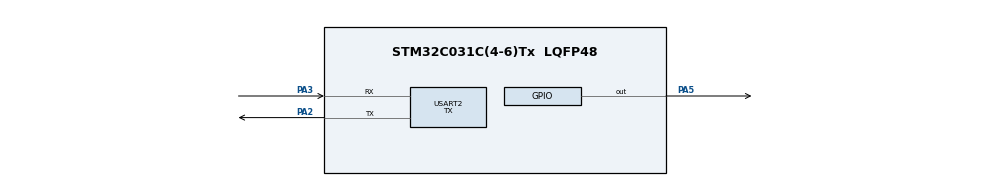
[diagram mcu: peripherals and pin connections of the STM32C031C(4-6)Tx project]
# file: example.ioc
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Mcu.Family=STM32C0
Mcu.Name=STM32C031C(4-6)Tx
Mcu.Package=LQFP48
NVIC.TimeBase=None
PA13.Mode=Serial_Wire
PA13.Signal=DEBUG_SWDIO
PA14-BOOT0.Mode=Serial_Wire
PA14-BOOT0.Signal=DEBUG_SWCLK
PA2.Mode=Asynchronous
PA2.Signal=USART2_TX
PA3.Mode=Asynchronous
PA3.Signal=USART2_RX
PA5.Signal=GPIO_Output
ProjectManager.HeapSize=0x200
ProjectManager.StackSize=0x400
ProjectManager.TargetToolchain=CMake
RCC.ADCFreq_Value=48000000
RCC.AHBFreq_Value=48000000
RCC.CortexFreq_Value=48000000
RCC.EXTERNAL_CLOCK_VALUE=12288000
RCC.HCLKFreq_Value=48000000
RCC.HSE_VALUE=8000000
RCC.HSISYSCLKDivider=RCC_HSI_DIV1
RCC.HSI_VALUE=48000000
RCC.LSE_VALUE=32768
RCC.SYSCLKFreq_VALUE=48000000
USART2.Mode=MODE_TX
USART2.VirtualMode-Asynchronous=VM_ASYNC
VP_SYS_VS_None.Mode=None
board=custom

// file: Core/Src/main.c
/* USER CODE BEGIN Header */
/**
  ******************************************************************************
  * @file           : main.c
  * @brief          : Main program body
  ******************************************************************************
  * @attention
  *
  * Copyright (c) 2026 STMicroelectronics.
  * All rights reserved.
  *
  * This software is licensed under terms that can be found in the LICENSE file
  * in the root directory of this software component.
  * If no LICENSE file comes with this software, it is provided AS-IS.
  *
  ******************************************************************************
  */
/* USER CODE END Header */
#include "main.h"

/* USER CODE BEGIN Includes */
#include "m0ss.h"
/* USER CODE END Includes */

/* USER CODE BEGIN PD */
#define BLINK_THREAD_STACK_BUF_CAPACITY 1024
#define UART_THREAD_STACK_BUF_CAPACITY 1024
/* USER CODE END PD */

UART_HandleTypeDef huart2;

/* USER CODE BEGIN PV */
_Alignas(8) static uint8_t blink_thread_stack_buf[BLINK_THREAD_STACK_BUF_CAPACITY];
_Alignas(8) static uint8_t uart_thread_stack_buf[UART_THREAD_STACK_BUF_CAPACITY];
/* USER CODE END PV */

void SystemClock_Config(void);
static void MX_GPIO_Init(void);
static void MX_USART2_UART_Init(void);
/* USER CODE BEGIN PFP */
void blink_thread_func()
{
    while (1) {
        HAL_GPIO_TogglePin(GPIOA, GPIO_PIN_5);

        m0ss_delay(250);
    }
}

void uart_thread_func()
{
    const char* message = "Hello, m0ss!\n";

    while (1) {
        HAL_UART_Transmit(&huart2, (uint8_t*)message, 13, HAL_MAX_DELAY);

        m0ss_delay(1000);
    }
}
/* USER CODE END PFP */

/* USER CODE BEGIN 0 */
// Note: Let the RTOS configure the SysTick.
HAL_StatusTypeDef HAL_InitTick(uint32_t TickPriority) {
    return HAL_OK;
}
/* USER CODE END 0 */

int main(void)
{

  /* MCU Configuration--------------------------------------------------------*/

  /* Reset of all peripherals, Initializes the Flash interface and the Systick. */
  HAL_Init();

  /* Configure the system clock */
  SystemClock_Config();

  /* Initialize all configured peripherals */
  MX_GPIO_Init();
  MX_USART2_UART_Init();
  /* USER CODE BEGIN 2 */
  m0ss_thread blink_thread;
  m0ss_thread uart_thread;

  m0ss_thread_create(&blink_thread, M0SS_THREAD_PRIORITY_LOWEST, blink_thread_func, blink_thread_stack_buf, BLINK_THREAD_STACK_BUF_CAPACITY);
  m0ss_thread_create(&uart_thread, M0SS_THREAD_PRIORITY_LOWEST + 1, uart_thread_func, uart_thread_stack_buf, UART_THREAD_STACK_BUF_CAPACITY);

  m0ss_start();
  /* USER CODE END 2 */

  /* Infinite loop */
  while (1)
  {

  }
}

void SystemClock_Config(void)
{
  RCC_OscInitTypeDef RCC_OscInitStruct = {0};
  RCC_ClkInitTypeDef RCC_ClkInitStruct = {0};

  __HAL_FLASH_SET_LATENCY(FLASH_LATENCY_1);

  /** Initializes the RCC Oscillators according to the specified parameters
  * in the RCC_OscInitTypeDef structure.
  */
  RCC_OscInitStruct.OscillatorType = RCC_OSCILLATORTYPE_HSI;
  RCC_OscInitStruct.HSIState = RCC_HSI_ON;
  RCC_OscInitStruct.HSIDiv = RCC_HSI_DIV1;
  RCC_OscInitStruct.HSICalibrationValue = RCC_HSICALIBRATION_DEFAULT;
  if (HAL_RCC_OscConfig(&RCC_OscInitStruct) != HAL_OK)
  {
    Error_Handler();
  }

  /** Initializes the CPU, AHB and APB buses clocks
  */
  RCC_ClkInitStruct.ClockType = RCC_CLOCKTYPE_HCLK|RCC_CLOCKTYPE_SYSCLK
                              |RCC_CLOCKTYPE_PCLK1;
  RCC_ClkInitStruct.SYSCLKSource = RCC_SYSCLKSOURCE_HSI;
  RCC_ClkInitStruct.SYSCLKDivider = RCC_SYSCLK_DIV1;
  RCC_ClkInitStruct.AHBCLKDivider = RCC_HCLK_DIV1;
  RCC_ClkInitStruct.APB1CLKDivider = RCC_APB1_DIV1;

  if (HAL_RCC_ClockConfig(&RCC_ClkInitStruct, FLASH_LATENCY_1) != HAL_OK)
  {
    Error_Handler();
  }
}

static void MX_USART2_UART_Init(void)
{

  huart2.Instance = USART2;
  huart2.Init.BaudRate = 115200;
  huart2.Init.WordLength = UART_WORDLENGTH_8B;
  huart2.Init.StopBits = UART_STOPBITS_1;
  huart2.Init.Parity = UART_PARITY_NONE;
  huart2.Init.Mode = UART_MODE_TX;
  huart2.Init.HwFlowCtl = UART_HWCONTROL_NONE;
  huart2.Init.OverSampling = UART_OVERSAMPLING_16;
  huart2.Init.OneBitSampling = UART_ONE_BIT_SAMPLE_DISABLE;
  huart2.Init.ClockPrescaler = UART_PRESCALER_DIV1;
  huart2.AdvancedInit.AdvFeatureInit = UART_ADVFEATURE_NO_INIT;
  if (HAL_UART_Init(&huart2) != HAL_OK)
  {
    Error_Handler();
  }

}

static void MX_GPIO_Init(void)
{
  GPIO_InitTypeDef GPIO_InitStruct = {0};

  /* GPIO Ports Clock Enable */
  __HAL_RCC_GPIOA_CLK_ENABLE();

  /*Configure GPIO pin Output Level */
  HAL_GPIO_WritePin(GPIOA, GPIO_PIN_5, GPIO_PIN_RESET);

  /*Configure GPIO pin : PA5 */
  GPIO_InitStruct.Pin = GPIO_PIN_5;
  GPIO_InitStruct.Mode = GPIO_MODE_OUTPUT_PP;
  GPIO_InitStruct.Pull = GPIO_NOPULL;
  GPIO_InitStruct.Speed = GPIO_SPEED_FREQ_LOW;
  HAL_GPIO_Init(GPIOA, &GPIO_InitStruct);

}

void Error_Handler(void)
{
  __disable_irq();
  while (1)
  {
  }
}
